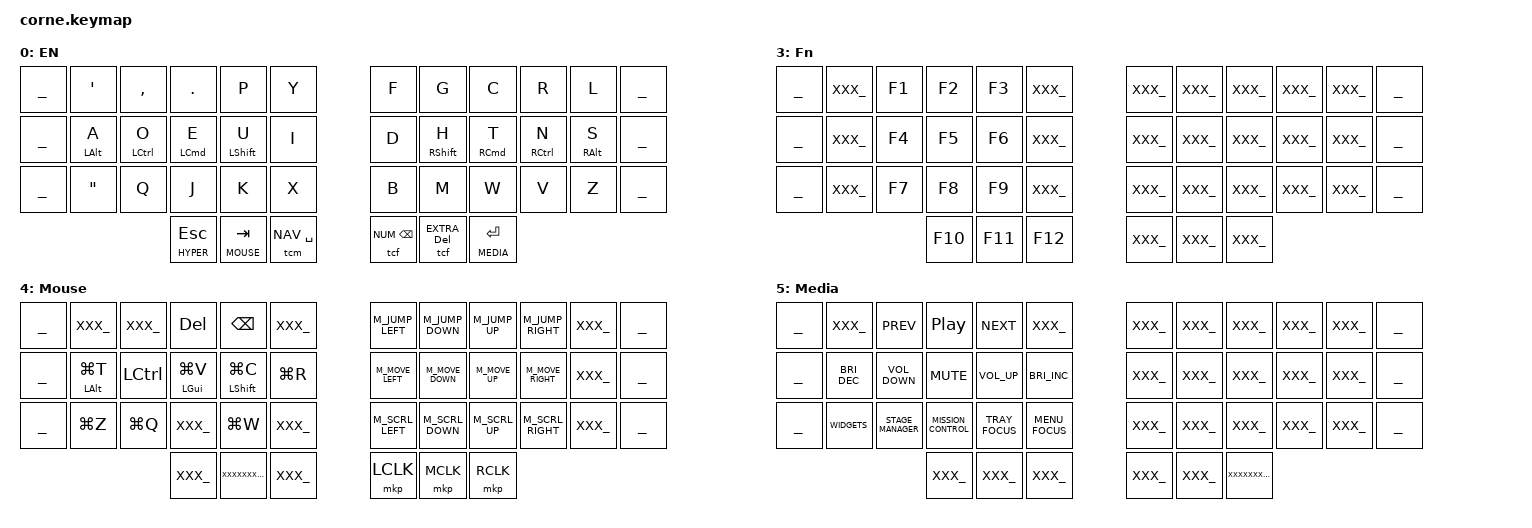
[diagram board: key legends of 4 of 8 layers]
/*                                       42 KEY MATRIX / LAYOUT MAPPING                                        */
/*  ╭────────────────────────┬────────────────────────╮ ╭─────────────────────────┬─────────────────────────╮  */
/*  │  0   1   2   3   4   5 │  6   7   8   9  10  11 │ │ LT5 LT4 LT3 LT2 LT1 LT0 │ RT0 RT1 RT2 RT3 RT4 RT5 │  */
/*  │ 12  13  14  15  16  17 │ 18  19  20  21  22  23 │ │ LM5 LM4 LM3 LM2 LM1 LM0 │ RM0 RM1 RM2 RM3 RM4 RM5 │  */
/*  │ 24  25  26  27  28  29 │ 30  31  32  33  34  35 │ │ LB5 LB4 LB3 LB2 LB1 LB0 │ RB0 RB1 RB2 RB3 RB4 RB5 │  */
/*  ╰───────────╮ 36  37  38 │ 39  40  41 ╭───────────╯ ╰───────────╮ LH2 LH1 LH0 │ RH0 RH1 RH2 ╭───────────╯  */
/*              ╰────────────┴────────────╯                         ╰─────────────┴─────────────╯              */

#define HOST_OS 2 // macOS

#include <behaviors.dtsi>

#include <dt-bindings/zmk/keys.h>
#include <dt-bindings/zmk/bt.h>

#include "zmk-helpers/helper.h"
#include "zmk-helpers/key-labels/42.h"

// Layers

#define BASE     0
#define NUM      1
#define NAV      2
#define EXTRA    3
#define RU_BASE  4
#define RU_NUM   5
#define RU_NAV   6
#define RU_EXTRA 7
#define FN       8
#define MOUSE    9
#define MEDIA    10
#define GLYPHS1  11
#define GLYPHS2  12
#define SYS      13

#include "modules/globals.dtsi"
#include "modules/hrms.dtsi"
#include "modules/behaviors.dtsi"
#include "modules/ru.dtsi"
#include "modules/mouse.dtsi"
#include "modules/symbols.dtsi"
#include "modules/combos.dtsi"

ZMK_LAYER(EN,
// ╭────┬───────────────────┬───────────────────┬───────────────────┬───────────────────┬───────────────────╮ ╭───────────────────┬───────────────────┬───────────────────┬───────────────────┬───────────────────┬────╮
     __        &kp SQT            &kp COMMA            &kp DOT              &kp P               &kp Y                 &kp F               &kp G               &kp C               &kp R                &kp L        __
// ├────┼───────────────────┼───────────────────┼───────────────────┼───────────────────┼───────────────────┤ ├───────────────────┼───────────────────┼───────────────────┼───────────────────┼───────────────────┼────┤
     __     &hrml LALT A        &hrml LCTRL O       &hrmlm LCMD E       &hrmlf LSHFT U          &kp I                 &kp D          &hrmrf RSHFT H       &hrmrm RCMD T       &hrmr RCTRL N       &hrmr RALT S      __
// ├────┼───────────────────┼───────────────────┼───────────────────┼───────────────────┼───────────────────┤ ├───────────────────┼───────────────────┼───────────────────┼───────────────────┼───────────────────┼────┤
     __        &kp DQT              &kp Q               &kp J               &kp K               &kp X                 &kp B               &kp M               &kp W               &kp V                &kp Z        __
// ╰────────────────────────────────────────────────────────────────┼───────────────────┼───────────────────┤ ├───────────────────┼───────────────────┼────────────────────────────────────────────────────────────────╯
                                                    &mt HYPER ESC       &lt MOUSE TAB       &tcm NAV SPACE        &tcf NUM BSPC       &tcf EXTRA DEL     &lt MEDIA ENTER
//                                              ╰───────────────────┴───────────────────┴───────────────────╯ ╰───────────────────┴───────────────────┴───────────────────╯
)

ZMK_LAYER(Num,
// ╭────┬───────────────────┬───────────────────┬───────────────────┬───────────────────┬───────────────────╮ ╭───────────────────┬───────────────────┬───────────────────┬───────────────────┬───────────────────┬────╮
     __       &kp COMMA             &kp N1             &kp N2              &kp N3              &kp AT               &kp TILDE           &kp SLASH       &kp LG(LC(LA(S)))     &kp QUESTION            &mo FN        __
// ├────┼───────────────────┼───────────────────┼───────────────────┼───────────────────┼───────────────────┤ ├───────────────────┼───────────────────┼───────────────────┼───────────────────┼───────────────────┼────┤
     __      &mt LALT N0        &mt LCTRL N4         &mt LCMD N5        &mt LSHFT N6          &kp PIPE              &kp UNDER        &mt RSHFT MINUS      &mt RCMD PLUS      &mt RCTRL EQUAL      &mt RALT SEMI     __
// ├────┼───────────────────┼───────────────────┼───────────────────┼───────────────────┼───────────────────┤ ├───────────────────┼───────────────────┼───────────────────┼───────────────────┼───────────────────┼────┤
     __        &kp DOT              &kp N7             &kp N8              &kp N9            &kp PERCENT              _XXX_               _XXX_               _XXX_                _XXX_              _XXX_         __
// ╰────────────────────────────────────────────────────────────────┼───────────────────┼───────────────────┤ ├───────────────────┼───────────────────┼────────────────────────────────────────────────────────────────╯
                                                        _TODO_              _____           &lt NAV SPACE       XXXXXXXXXXXXXXXXX         _XXX_               _XXX_
//                                              ╰───────────────────┴───────────────────┴───────────────────╯ ╰───────────────────┴───────────────────┴───────────────────╯
)

ZMK_LAYER(Nav,
// ╭────┬───────────────────┬───────────────────┬───────────────────┬───────────────────┬───────────────────╮ ╭───────────────────┬───────────────────┬───────────────────┬───────────────────┬───────────────────┬────╮
     __     &kp CAPSLOCK         &sl GLYPHS1      &kp LG(LC(LA(J)))     &kp ASTERISK          &kp UNDER              &kp HASH          &cur_sqr_l           &cur_sqr_r       &kp EXCLAMATION       &lang_switch     __
// ├────┼───────────────────┼───────────────────┼───────────────────┼───────────────────┼───────────────────┤ ├───────────────────┼───────────────────┼───────────────────┼───────────────────┼───────────────────┼────┤
     __    CAPS_WORD(LALT)       &kp LCTRL        &hrml LCMD COLON     &hrml LSHFT ESC      &kp AMPERSAND            &kp LEFT           &kp DOWN              &kp UP            &kp RIGHT             _XXX_         __
// ├────┼───────────────────┼───────────────────┼───────────────────┼───────────────────┼───────────────────┤ ├───────────────────┼───────────────────┼───────────────────┼───────────────────┼───────────────────┼────┤
     __         _XXX_               _XXX_               _XXX_               _XXX_               _XXX_                 _XXX_             &par_ang_l          &par_ang_r        &kp BACKSLASH           _XXX_         __
// ╰────────────────────────────────────────────────────────────────┼───────────────────┼───────────────────┤ ├───────────────────┼───────────────────┼────────────────────────────────────────────────────────────────╯
                                                        _XXX_               _XXX_         XXXXXXXXXXXXXXXXX         &kp ENTER            &kp TAB             _TODO_
//                                              ╰───────────────────┴───────────────────┴───────────────────╯ ╰───────────────────┴───────────────────┴───────────────────╯
)

ZMK_LAYER(Extra,
// ╭────┬───────────────────┬───────────────────┬───────────────────┬───────────────────┬───────────────────╮ ╭───────────────────┬───────────────────┬───────────────────┬───────────────────┬───────────────────┬────╮
     __         _XXX_               _XXX_               _XXX_               _XXX_               _XXX_                 _XXX_               _XXX_               _XXX_               _XXX_               _XXX_         __
// ├────┼───────────────────┼───────────────────┼───────────────────┼───────────────────┼───────────────────┤ ├───────────────────┼───────────────────┼───────────────────┼───────────────────┼───────────────────┼────┤
     __       &fat_arrow            _XXX_              &kp LCMD            &kp GRAVE            _XXX_                 _XXX_               _XXX_               _XXX_               _XXX_               _XXX_         __
// ├────┼───────────────────┼───────────────────┼───────────────────┼───────────────────┼───────────────────┤ ├───────────────────┼───────────────────┼───────────────────┼───────────────────┼───────────────────┼────┤
     __         &arrow             &kp N0             &kp CARET           &kp DOLLAR          &kp PERCENT             _XXX_               _XXX_               _XXX_               _XXX_               _XXX_         __
// ╰────────────────────────────────────────────────────────────────┼───────────────────┼───────────────────┤ ├───────────────────┼───────────────────┼────────────────────────────────────────────────────────────────╯
                                                        _XXX_               _XXX_               _XXX_                 _XXX_         XXXXXXXXXXXXXXXXX         _XXX_
//                                              ╰───────────────────┴───────────────────┴───────────────────╯ ╰───────────────────┴───────────────────┴───────────────────╯
)

ZMK_LAYER(RU,
// ╭────┬───────────────────┬───────────────────┬───────────────────┬───────────────────┬───────────────────╮ ╭───────────────────┬───────────────────┬───────────────────┬───────────────────┬───────────────────┬────╮
     __         &ru_ii              &ru_ts              &ru_u               &ru_k               &ru_e                 &ru_n               &ru_g              &ru_sh              &ru_shch              &ru_z        __
// ├────┼───────────────────┼───────────────────┼───────────────────┼───────────────────┼───────────────────┤ ├───────────────────┼───────────────────┼───────────────────┼───────────────────┼───────────────────┼────┤
     __        RU_F_HRM            RU_YI_HRM           RU_V_HRM            RU_A_HRM             &ru_p                 &ru_r              RU_O_HRM            RU_L_HRM            RU_D_HRM            RU_ZH_HRM      __
// ├────┼───────────────────┼───────────────────┼───────────────────┼───────────────────┼───────────────────┤ ├───────────────────┼───────────────────┼───────────────────┼───────────────────┼───────────────────┼────┤
     __         &ru_ya              &ru_ch              &ru_s               &ru_m               &ru_i                 &ru_t              &ru_soft             &ru_b               &ru_yu              &ru_ye        __
// ╰────────────────────────────────────────────────────────────────┼───────────────────┼───────────────────┤ ├───────────────────┼───────────────────┼────────────────────────────────────────────────────────────────╯
                                                    &mt HYPER ESC       &lt MOUSE TAB     &tcn RU_NAV SPACE      &tcf RU_NUM BSPC   &tcf RU_EXTRA DEL    &lt MEDIA ENTER
//                                              ╰───────────────────┴───────────────────┴───────────────────╯ ╰───────────────────┴───────────────────┴───────────────────╯
)

ZMK_LAYER(RU-Num,
// ╭────┬───────────────────┬───────────────────┬───────────────────┬───────────────────┬───────────────────╮ ╭───────────────────┬───────────────────┬───────────────────┬───────────────────┬───────────────────┬────╮
     __      &kp RU_COMMA           &kp N1             &kp N2              &kp N3             &kp RU_AT            &kp RU_TILDE        &kp RU_SLASH     &kp LG(LC(LA(S)))    &kp RU_QUESTION          &mo FN        __
// ├────┼───────────────────┼───────────────────┼───────────────────┼───────────────────┼───────────────────┤ ├───────────────────┼───────────────────┼───────────────────┼───────────────────┼───────────────────┼────┤
     __      &mt LALT N0        &mt LCTRL N4          &ru_n5_dot         &ru_n6_comma        &kp RU_PIPE           &kp RU_UNDER     &mt RSHFT RU_MINUS   &mt RCMD RU_PLUS    &mt RCTRL EQUAL    &mt RALT RU_SEMI    __
// ├────┼───────────────────┼───────────────────┼───────────────────┼───────────────────┼───────────────────┤ ├───────────────────┼───────────────────┼───────────────────┼───────────────────┼───────────────────┼────┤
     __       &kp RU_DOT            &kp N7            &ru_n8_sqt          &ru_n9_dqt        &kp RU_PERCENT            _XXX_               _XXX_               _XXX_               _XXX_               _XXX_         __
// ╰────────────────────────────────────────────────────────────────┼───────────────────┼───────────────────┤ ├───────────────────┼───────────────────┼────────────────────────────────────────────────────────────────╯
                                                        _TODO_              _____          &lt RU_NAV SPACE     XXXXXXXXXXXXXXXXX         _XXX_               _XXX_
//                                              ╰───────────────────┴───────────────────┴───────────────────╯ ╰───────────────────┴───────────────────┴───────────────────╯
)

ZMK_LAYER(RU-Nav,
// ╭────┬───────────────────┬───────────────────┬───────────────────┬───────────────────┬───────────────────╮ ╭───────────────────┬───────────────────┬───────────────────┬───────────────────┬───────────────────┬────╮
     __     &kp CAPSLOCK            _XXX_         &kp LG(LC(LA(J)))    &kp RU_ASTERISK       &kp RU_UNDER          &kp RU_HASH        &ru_cur_sqr_l       &ru_cur_sqr_r    &kp RU_EXCLAMATION      &lang_switch     __
// ├────┼───────────────────┼───────────────────┼───────────────────┼───────────────────┼───────────────────┤ ├───────────────────┼───────────────────┼───────────────────┼───────────────────┼───────────────────┼────┤
     __    CAPS_WORD(LALT)       &kp LCTRL       &hrml LCMD RU_COLON   &hrml LSHFT ESC     &kp RU_AMPERSAND          &kp LEFT           &kp DOWN              &kp UP            &kp RIGHT           &kp RU_H        __
// ├────┼───────────────────┼───────────────────┼───────────────────┼───────────────────┼───────────────────┤ ├───────────────────┼───────────────────┼───────────────────┼───────────────────┼───────────────────┼────┤
     __         _XXX_               _XXX_               _XXX_               _XXX_               _XXX_                 _XXX_           &ru_par_ang_l        &ru_par_ang_r        &kp RU_YO          &kp RU_HARD      __
// ╰────────────────────────────────────────────────────────────────┼───────────────────┼───────────────────┤ ├───────────────────┼───────────────────┼────────────────────────────────────────────────────────────────╯
                                                        _XXX_               _XXX_         XXXXXXXXXXXXXXXXX         &kp ENTER            &kp TAB              _TODO_
//                                              ╰───────────────────┴───────────────────┴───────────────────╯ ╰───────────────────┴───────────────────┴───────────────────╯
)

ZMK_LAYER(RU-Extra,
// ╭────┬───────────────────┬───────────────────┬───────────────────┬───────────────────┬───────────────────╮ ╭───────────────────┬───────────────────┬───────────────────┬───────────────────┬───────────────────┬────╮
     __         _XXX_               _XXX_               _XXX_               _XXX_               _XXX_                 _XXX_               _XXX_               _XXX_               _XXX_               _XXX_         __
// ├────┼───────────────────┼───────────────────┼───────────────────┼───────────────────┼───────────────────┤ ├───────────────────┼───────────────────┼───────────────────┼───────────────────┼───────────────────┼────┤
     __     &ru_fat_arrow           _XXX_              &kp LCMD          &kp RU_GRAVE           _XXX_                 _XXX_               _XXX_               _XXX_               _XXX_               _XXX_         __
// ├────┼───────────────────┼───────────────────┼───────────────────┼───────────────────┼───────────────────┤ ├───────────────────┼───────────────────┼───────────────────┼───────────────────┼───────────────────┼────┤
     __       &ru_arrow             &kp N0           &kp RU_CARET       &kp RU_DOLLAR       &kp RU_PERCENT            _XXX_               _XXX_               _XXX_               _XXX_               _XXX_         __
// ╰────────────────────────────────────────────────────────────────┼───────────────────┼───────────────────┤ ├───────────────────┼───────────────────┼────────────────────────────────────────────────────────────────╯
                                                        _XXX_               _XXX_               _XXX_                 _XXX_         XXXXXXXXXXXXXXXXX         _XXX_
//                                              ╰───────────────────┴───────────────────┴───────────────────╯ ╰───────────────────┴───────────────────┴───────────────────╯
)

ZMK_LAYER(Fn,
// ╭────┬───────────────────┬───────────────────┬───────────────────┬───────────────────┬───────────────────╮ ╭───────────────────┬───────────────────┬───────────────────┬───────────────────┬───────────────────┬────╮
     __         _XXX_               &kp F1              &kp F2              &kp F3              _XXX_                 _XXX_               _XXX_               _XXX_               _XXX_               _XXX_         __
// ├────┼───────────────────┼───────────────────┼───────────────────┼───────────────────┼───────────────────┤ ├───────────────────┼───────────────────┼───────────────────┼───────────────────┼───────────────────┼────┤
     __         _XXX_               &kp F4              &kp F5              &kp F6              _XXX_                 _XXX_               _XXX_               _XXX_               _XXX_               _XXX_         __
// ├────┼───────────────────┼───────────────────┼───────────────────┼───────────────────┼───────────────────┤ ├───────────────────┼───────────────────┼───────────────────┼───────────────────┼───────────────────┼────┤
     __         _XXX_               &kp F7              &kp F8              &kp F9              _XXX_                 _XXX_               _XXX_               _XXX_               _XXX_               _XXX_         __
// ╰────────────────────────────────────────────────────────────────┼───────────────────┼───────────────────┤ ├───────────────────┼───────────────────┼────────────────────────────────────────────────────────────────╯
                                                       &kp F10             &kp F11             &kp F12                _XXX_               _XXX_               _XXX_
//                                              ╰───────────────────┴───────────────────┴───────────────────╯ ╰───────────────────┴───────────────────┴───────────────────╯
)

ZMK_LAYER(Mouse,
// ╭────┬───────────────────┬───────────────────┬───────────────────┬───────────────────┬───────────────────╮ ╭───────────────────┬───────────────────┬───────────────────┬───────────────────┬───────────────────┬────╮
     __         _XXX_               _XXX_              &kp DEL             &kp BSPC             _XXX_              M_JUMP_LEFT         M_JUMP_DOWN          M_JUMP_UP          M_JUMP_RIGHT           _XXX_         __
// ├────┼───────────────────┼───────────────────┼───────────────────┼───────────────────┼───────────────────┤ ├───────────────────┼───────────────────┼───────────────────┼───────────────────┼───────────────────┼────┤
     __     &mt LALT LG(T)        &kp LCTRL         &mt LGUI LG(V)     &mt LSHFT LG(C)        &kp LG(R)            M_MOVE_LEFT         M_MOVE_DOWN          M_MOVE_UP          M_MOVE_RIGHT           _XXX_         __
// ├────┼───────────────────┼───────────────────┼───────────────────┼───────────────────┼───────────────────┤ ├───────────────────┼───────────────────┼───────────────────┼───────────────────┼───────────────────┼────┤
     __       &kp LG(Z)           &kp LG(Q)             _XXX_             &kp LG(W)             _XXX_              M_SCRL_LEFT         M_SCRL_DOWN          M_SCRL_UP          M_SCRL_RIGHT           _XXX_         __
// ╰────────────────────────────────────────────────────────────────┼───────────────────┼───────────────────┤ ├───────────────────┼───────────────────┼────────────────────────────────────────────────────────────────╯
                                                        _XXX_         XXXXXXXXXXXXXXXXX         _XXX_               &mkp LCLK           &mkp MCLK           &mkp RCLK
//                                              ╰───────────────────┴───────────────────┴───────────────────╯ ╰───────────────────┴───────────────────┴───────────────────╯
)

ZMK_LAYER(Media,
// ╭────┬───────────────────┬───────────────────┬───────────────────┬───────────────────┬───────────────────╮ ╭───────────────────┬───────────────────┬───────────────────┬───────────────────┬───────────────────┬────╮
     __         _XXX_             &kp C_PREV       &kp C_PLAY_PAUSE       &kp C_NEXT            _XXX_                 _XXX_               _XXX_               _XXX_               _XXX_               _XXX_         __
// ├────┼───────────────────┼───────────────────┼───────────────────┼───────────────────┼───────────────────┤ ├───────────────────┼───────────────────┼───────────────────┼───────────────────┼───────────────────┼────┤
     __     &kp C_BRI_DEC     &kp C_VOLUME_DOWN       &kp C_MUTE       &kp C_VOLUME_UP      &kp C_BRI_INC             _XXX_               _XXX_               _XXX_               _XXX_               _XXX_         __
// ├────┼───────────────────┼───────────────────┼───────────────────┼───────────────────┼───────────────────┤ ├───────────────────┼───────────────────┼───────────────────┼───────────────────┼───────────────────┼────┤
     __      &kp WIDGETS      &kp STAGE_MANAGER  &kp MISSION_CONTROL    &kp TRAY_FOCUS     &kp MENU_FOCUS             _XXX_               _XXX_               _XXX_               _XXX_               _XXX_         __
// ╰────────────────────────────────────────────────────────────────┼───────────────────┼───────────────────┤ ├───────────────────┼───────────────────┼────────────────────────────────────────────────────────────────╯
                                                        _XXX_               _XXX_               _XXX_                 _XXX_               _XXX_         XXXXXXXXXXXXXXXXX
//                                              ╰───────────────────┴───────────────────┴───────────────────╯ ╰───────────────────┴───────────────────┴───────────────────╯
)

ZMK_LAYER(Glyphs,
// ╭────┬───────────────────┬───────────────────┬───────────────────┬───────────────────┬───────────────────╮ ╭───────────────────┬───────────────────┬───────────────────┬───────────────────┬───────────────────┬────╮
     __         _XXX_               _XXX_               _XXX_               _XXX_               _XXX_                 _XXX_               _XXX_               _XXX_               _XXX_               _XXX_         __
// ├────┼───────────────────┼───────────────────┼───────────────────┼───────────────────┼───────────────────┤ ├───────────────────┼───────────────────┼───────────────────┼───────────────────┼───────────────────┼────┤
     __         &g_opt             &g_ctrl              &g_cmd             &g_shift             _XXX_                &g_left             &g_down              &g_up              &g_right             _XXX_         __
// ├────┼───────────────────┼───────────────────┼───────────────────┼───────────────────┼───────────────────┤ ├───────────────────┼───────────────────┼───────────────────┼───────────────────┼───────────────────┼────┤
     __         _XXX_               _XXX_               _XXX_               _XXX_            &g_multiply              _XXX_               _XXX_               _XXX_               _XXX_               _XXX_         __
// ╰────────────────────────────────────────────────────────────────┼───────────────────┼───────────────────┤ ├───────────────────┼───────────────────┼────────────────────────────────────────────────────────────────╯
                                                        _XXX_               &g_tab            LT_G_SPACE           &g_backspace         &g_delete             _XXX_
//                                              ╰───────────────────┴───────────────────┴───────────────────╯ ╰───────────────────┴───────────────────┴───────────────────╯
)

ZMK_LAYER(Glyphs+,
// ╭────┬───────────────────┬───────────────────┬───────────────────┬───────────────────┬───────────────────╮ ╭───────────────────┬───────────────────┬───────────────────┬───────────────────┬───────────────────┬────╮
     __         _XXX_               _XXX_               _XXX_               _XXX_               _XXX_                 _XXX_               _XXX_               _XXX_               _XXX_               _XXX_         __
// ├────┼───────────────────┼───────────────────┼───────────────────┼───────────────────┼───────────────────┤ ├───────────────────┼───────────────────┼───────────────────┼───────────────────┼───────────────────┼────┤
     __         _XXX_               _XXX_               _XXX_               &g_esc              _XXX_                 _XXX_               _XXX_               _XXX_               _XXX_               _XXX_         __
// ├────┼───────────────────┼───────────────────┼───────────────────┼───────────────────┼───────────────────┤ ├───────────────────┼───────────────────┼───────────────────┼───────────────────┼───────────────────┼────┤
     __         _XXX_               _XXX_               _XXX_               _XXX_               _XXX_                 _XXX_               _XXX_               _XXX_               _XXX_               _XXX_         __
// ╰────────────────────────────────────────────────────────────────┼───────────────────┼───────────────────┤ ├───────────────────┼───────────────────┼────────────────────────────────────────────────────────────────╯
                                                        _XXX_               _XXX_         XXXXXXXXXXXXXXXXX         &g_return            &g_tab               _XXX_
//                                              ╰───────────────────┴───────────────────┴───────────────────╯ ╰───────────────────┴───────────────────┴───────────────────╯
)

ZMK_LAYER(Sys,
// ╭────┬───────────────────┬───────────────────┬───────────────────┬───────────────────┬───────────────────╮ ╭───────────────────┬───────────────────┬───────────────────┬───────────────────┬───────────────────┬────╮
     __         _XXX_               _XXX_               _XXX_               _XXX_               _XXX_                 _XXX_               _XXX_               _XXX_               _XXX_               _XXX_         __
// ├────┼───────────────────┼───────────────────┼───────────────────┼───────────────────┼───────────────────┤ ├───────────────────┼───────────────────┼───────────────────┼───────────────────┼───────────────────┼────┤
     __         _XXX_               _XXX_               _XXX_            &bootloader            _XXX_                 _XXX_               _XXX_               _XXX_               _XXX_               _XXX_         __
// ├────┼───────────────────┼───────────────────┼───────────────────┼───────────────────┼───────────────────┤ ├───────────────────┼───────────────────┼───────────────────┼───────────────────┼───────────────────┼────┤
     __    &bt BT_CLR_ALL           _XXX_               _XXX_               _XXX_               _XXX_                 _XXX_               _XXX_               _XXX_               _XXX_               _XXX_         __
// ╰────────────────────────────────────────────────────────────────┼───────────────────┼───────────────────┤ ├───────────────────┼───────────────────┼────────────────────────────────────────────────────────────────╯
                                                        _XXX_               _XXX_           &kp LANG_FIX              _XXX_               _XXX_               _XXX_
//                                              ╰───────────────────┴───────────────────┴───────────────────╯ ╰───────────────────┴───────────────────┴───────────────────╯
)
